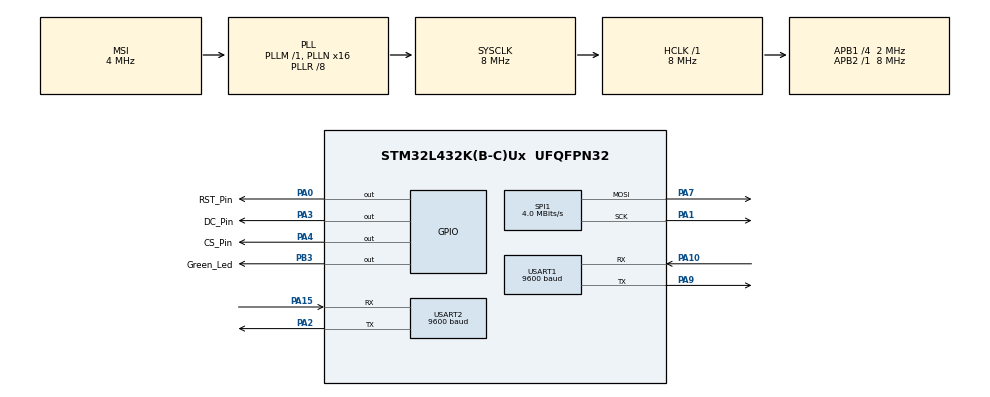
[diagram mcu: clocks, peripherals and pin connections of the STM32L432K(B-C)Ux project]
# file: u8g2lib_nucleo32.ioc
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Dma.Request0=SPI1_TX
Dma.SPI1_TX.0.Direction=DMA_MEMORY_TO_PERIPH
Dma.SPI1_TX.0.Instance=DMA1_Channel3
Dma.SPI1_TX.0.MemDataAlignment=DMA_MDATAALIGN_BYTE
Dma.SPI1_TX.0.MemInc=DMA_MINC_ENABLE
Dma.SPI1_TX.0.Mode=DMA_NORMAL
Dma.SPI1_TX.0.PeriphDataAlignment=DMA_PDATAALIGN_BYTE
Dma.SPI1_TX.0.PeriphInc=DMA_PINC_DISABLE
Dma.SPI1_TX.0.Priority=DMA_PRIORITY_LOW
Mcu.Family=STM32L4
Mcu.Name=STM32L432K(B-C)Ux
Mcu.Package=UFQFPN32
NVIC.DMA1_Channel3_IRQn=true\:0\:0\:false\:false\:true\:false\:true
NVIC.PriorityGroup=NVIC_PRIORITYGROUP_4
NVIC.SPI1_IRQn=true\:0\:0\:false\:false\:true\:true\:true
NVIC.USART2_IRQn=true\:0\:0\:false\:false\:true\:true\:true
PA0.GPIO_Label=RST_Pin
PA0.GPIO_Speed=GPIO_SPEED_FREQ_HIGH
PA0.Signal=GPIO_Output
PA1.GPIO_Speed=GPIO_SPEED_FREQ_HIGH
PA1.Mode=TX_Only_Simplex_Unidirect_Master
PA1.Signal=SPI1_SCK
PA10.GPIO_Speed=GPIO_SPEED_FREQ_MEDIUM
PA10.Mode=Asynchronous
PA10.Signal=USART1_RX
PA13\ (JTMS-SWDIO).Mode=Serial_Wire
PA13\ (JTMS-SWDIO).Signal=SYS_JTMS-SWDIO
PA14\ (JTCK-SWCLK).Mode=Serial_Wire
PA14\ (JTCK-SWCLK).Signal=SYS_JTCK-SWCLK
PA15\ (JTDI).GPIO_Mode=GPIO_MODE_AF_PP
PA15\ (JTDI).GPIO_PuPd=GPIO_PULLUP
PA15\ (JTDI).GPIO_Speed=GPIO_SPEED_FREQ_VERY_HIGH
PA15\ (JTDI).Mode=Asynchronous
PA15\ (JTDI).Signal=USART2_RX
PA2.GPIO_Mode=GPIO_MODE_AF_PP
PA2.GPIO_PuPd=GPIO_PULLUP
PA2.GPIO_Speed=GPIO_SPEED_FREQ_VERY_HIGH
PA2.Mode=Asynchronous
PA2.Signal=USART2_TX
PA3.GPIO_Label=DC_Pin
PA3.GPIO_ModeDefaultOutputPP=GPIO_MODE_OUTPUT_PP
PA3.GPIO_PuPd=GPIO_NOPULL
PA3.GPIO_Speed=GPIO_SPEED_FREQ_HIGH
PA3.PinState=GPIO_PIN_RESET
PA3.Signal=GPIO_Output
PA4.GPIO_Label=CS_Pin
PA4.GPIO_Speed=GPIO_SPEED_FREQ_HIGH
PA4.Signal=GPIO_Output
PA7.GPIO_Speed=GPIO_SPEED_FREQ_HIGH
PA7.Mode=TX_Only_Simplex_Unidirect_Master
PA7.Signal=SPI1_MOSI
PA9.GPIO_Speed=GPIO_SPEED_FREQ_MEDIUM
PA9.Mode=Asynchronous
PA9.Signal=USART1_TX
PB3\ (JTDO-TRACESWO).GPIO_Label=Green_Led
PB3\ (JTDO-TRACESWO).Signal=GPIO_Output
PC14-OSC32_IN\ (PC14).Signal=RCC_OSC32_IN
PC15-OSC32_OUT\ (PC15).Signal=RCC_OSC32_OUT
ProjectManager.HeapSize=0x200
ProjectManager.StackSize=0x400
ProjectManager.TargetToolchain=SW4STM32
RCC.ADCFreq_Value=16000000
RCC.AHBFreq_Value=8000000
RCC.APB1CLKDivider=RCC_HCLK_DIV4
RCC.APB1Freq_Value=2000000
RCC.APB1TimFreq_Value=4000000
RCC.APB2Freq_Value=8000000
RCC.APB2TimFreq_Value=8000000
RCC.CortexFreq_Value=8000000
RCC.HCLKFreq_Value=8000000
RCC.HSE_VALUE=8000000
RCC.HSI48_VALUE=48000000
RCC.HSI_VALUE=16000000
RCC.LSE_VALUE=32768
RCC.MSI_VALUE=4000000
RCC.PLLN=16
RCC.PLLR=RCC_PLLR_DIV8
RCC.PREFETCH_ENABLE=1
RCC.SYSCLKFreq_VALUE=8000000
RCC.SYSCLKSource=RCC_SYSCLKSOURCE_PLLCLK
RCC.USBFreq_Value=16000000
RCC.VCOOutputFreq_Value=64000000
RTC.Format=RTC_FORMAT_BIN
RTC.Year=0
SPI1.CLKPhase=SPI_PHASE_2EDGE
SPI1.CLKPolarity=SPI_POLARITY_HIGH
SPI1.CalculateBaudRate=4.0 MBits/s
SPI1.DataSize=SPI_DATASIZE_8BIT
SPI1.Direction=SPI_DIRECTION_2LINES
SPI1.Mode=SPI_MODE_MASTER
SPI1.VirtualType=VM_MASTER
USART1.BaudRate=9600
USART1.VirtualMode-Asynchronous=VM_ASYNC
USART2.BaudRate=9600
USART2.VirtualMode-Asynchronous=VM_ASYNC
USART2.WordLength=WORDLENGTH_8B
VP_CRC_VS_CRC.Mode=CRC_Activate
VP_RTC_VS_RTC_Activate.Mode=RTC_Enabled
VP_RTC_VS_RTC_Calendar.Mode=RTC_Calendar
board=NUCLEO-L432KC

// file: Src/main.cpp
/* USER CODE BEGIN Header */
/**
  ******************************************************************************
  * @file           : main.c
  * @brief          : Main program body
  ******************************************************************************
  ** This notice applies to any and all portions of this file
  * that are not between comment pairs USER CODE BEGIN and
  * USER CODE END. Other portions of this file, whether
  * inserted by the user or by software development tools
  * are owned by their respective copyright owners.
  *
  * COPYRIGHT(c) 2019 STMicroelectronics
  *
  * Redistribution and use in source and binary forms, with or without modification,
  * are permitted provided that the following conditions are met:
  *   1. Redistributions of source code must retain the above copyright notice,
  *      this list of conditions and the following disclaimer.
  *   2. Redistributions in binary form must reproduce the above copyright notice,
  *      this list of conditions and the following disclaimer in the documentation
  *      and/or other materials provided with the distribution.
  *   3. Neither the name of STMicroelectronics nor the names of its contributors
  *      may be used to endorse or promote products derived from this software
  *      without specific prior written permission.
  *
  * THIS SOFTWARE IS PROVIDED BY THE COPYRIGHT HOLDERS AND CONTRIBUTORS "AS IS"
  * AND ANY EXPRESS OR IMPLIED WARRANTIES, INCLUDING, BUT NOT LIMITED TO, THE
  * IMPLIED WARRANTIES OF MERCHANTABILITY AND FITNESS FOR A PARTICULAR PURPOSE ARE
  * DISCLAIMED. IN NO EVENT SHALL THE COPYRIGHT HOLDER OR CONTRIBUTORS BE LIABLE
  * FOR ANY DIRECT, INDIRECT, INCIDENTAL, SPECIAL, EXEMPLARY, OR CONSEQUENTIAL
  * DAMAGES (INCLUDING, BUT NOT LIMITED TO, PROCUREMENT OF SUBSTITUTE GOODS OR
  * SERVICES; LOSS OF USE, DATA, OR PROFITS; OR BUSINESS INTERRUPTION) HOWEVER
  * CAUSED AND ON ANY THEORY OF LIABILITY, WHETHER IN CONTRACT, STRICT LIABILITY,
  * OR TORT (INCLUDING NEGLIGENCE OR OTHERWISE) ARISING IN ANY WAY OUT OF THE USE
  * OF THIS SOFTWARE, EVEN IF ADVISED OF THE POSSIBILITY OF SUCH DAMAGE.
  *
  ******************************************************************************
  */
/* USER CODE END Header */

#include "main.h"
#include "crc.h"
#include "dma.h"
#include "rtc.h"
#include "spi.h"
#include "usart.h"
#include "gpio.h"

/* USER CODE BEGIN Includes */
#include "u8g2/u8g2lib.hpp"
/* USER CODE END Includes */

void SystemClock_Config(void);

int main(void)
{

  /* MCU Configuration--------------------------------------------------------*/

  /* Reset of all peripherals, Initializes the Flash interface and the Systick. */
  HAL_Init();

  /* Configure the system clock */
  SystemClock_Config();

  /* Initialize all configured peripherals */
  MX_GPIO_Init();
  MX_DMA_Init();
  MX_USART2_UART_Init();
  MX_RTC_Init();
  MX_CRC_Init();
  MX_SPI1_Init();
  MX_USART1_UART_Init();
  /* USER CODE BEGIN 2 */
  using namespace u8g2lib;
  U8G2<CHIP_TYPE::SH1106, INTERFACE::SPI_4W_HW, DISPLAY::NONAME_128x64, MODE::FULL_PAGE> u8g2(U8G2_R0);
  u8g2.begin();
  u8g2.setContrast(0);
  //u8g2.enableUTF8Print();
  u8g2.setFont(u8g2_font_unifont_t_greek);
 // u8g2.setFont(u8g2_font_unifont_t_extended);
 // u8g2.setFont(u8g2_font_unifont_t_chinese2);

  uint32_t x = 0;
  uint32_t y = 30;
  /* USER CODE END 2 */

  /* Infinite loop */
  /* USER CODE BEGIN WHILE */
  auto n = 3000U;
  auto page = 0U;
  while (1)
  {
    /* USER CODE END WHILE */

  }
}

void SystemClock_Config(void)
{
  RCC_OscInitTypeDef RCC_OscInitStruct = {0};
  RCC_ClkInitTypeDef RCC_ClkInitStruct = {0};
  RCC_PeriphCLKInitTypeDef PeriphClkInit = {0};

  /** Initializes the CPU, AHB and APB busses clocks
  */
  RCC_OscInitStruct.OscillatorType = RCC_OSCILLATORTYPE_LSI|RCC_OSCILLATORTYPE_MSI;
  RCC_OscInitStruct.LSIState = RCC_LSI_ON;
  RCC_OscInitStruct.MSIState = RCC_MSI_ON;
  RCC_OscInitStruct.MSICalibrationValue = 0;
  RCC_OscInitStruct.MSIClockRange = RCC_MSIRANGE_6;
  RCC_OscInitStruct.PLL.PLLState = RCC_PLL_ON;
  RCC_OscInitStruct.PLL.PLLSource = RCC_PLLSOURCE_MSI;
  RCC_OscInitStruct.PLL.PLLM = 1;
  RCC_OscInitStruct.PLL.PLLN = 16;
  RCC_OscInitStruct.PLL.PLLP = RCC_PLLP_DIV7;
  RCC_OscInitStruct.PLL.PLLQ = RCC_PLLQ_DIV2;
  RCC_OscInitStruct.PLL.PLLR = RCC_PLLR_DIV8;
  if (HAL_RCC_OscConfig(&RCC_OscInitStruct) != HAL_OK)
  {
    Error_Handler();
  }
  /** Initializes the CPU, AHB and APB busses clocks
  */
  RCC_ClkInitStruct.ClockType = RCC_CLOCKTYPE_HCLK|RCC_CLOCKTYPE_SYSCLK
                              |RCC_CLOCKTYPE_PCLK1|RCC_CLOCKTYPE_PCLK2;
  RCC_ClkInitStruct.SYSCLKSource = RCC_SYSCLKSOURCE_PLLCLK;
  RCC_ClkInitStruct.AHBCLKDivider = RCC_SYSCLK_DIV1;
  RCC_ClkInitStruct.APB1CLKDivider = RCC_HCLK_DIV4;
  RCC_ClkInitStruct.APB2CLKDivider = RCC_HCLK_DIV1;

  if (HAL_RCC_ClockConfig(&RCC_ClkInitStruct, FLASH_LATENCY_0) != HAL_OK)
  {
    Error_Handler();
  }
  PeriphClkInit.PeriphClockSelection = RCC_PERIPHCLK_RTC|RCC_PERIPHCLK_USART1
                              |RCC_PERIPHCLK_USART2;
  PeriphClkInit.Usart1ClockSelection = RCC_USART1CLKSOURCE_PCLK2;
  PeriphClkInit.Usart2ClockSelection = RCC_USART2CLKSOURCE_PCLK1;
  PeriphClkInit.RTCClockSelection = RCC_RTCCLKSOURCE_LSI;
  if (HAL_RCCEx_PeriphCLKConfig(&PeriphClkInit) != HAL_OK)
  {
    Error_Handler();
  }
  /** Configure the main internal regulator output voltage
  */
  if (HAL_PWREx_ControlVoltageScaling(PWR_REGULATOR_VOLTAGE_SCALE1) != HAL_OK)
  {
    Error_Handler();
  }
}

void Error_Handler(void)
{
}

/************************ (C) COPYRIGHT STMicroelectronics *****END OF FILE****/
